AUTOSAR XML (schema 4.0)
standard types defined: float32, float64, sint16, sint32, sint8, uint16, uint32, uint8, void, boolean
package /MappingSets
  data type mapping set MappingSet
package /PortInterfaces/ClientServer
  7 x client server interface:
    CsIf_HeightMotor
      operation Opr_MoveOperation
        arg Arg_MotorRead: type=uint8, direction=IN
    CsIf_HeightSensor
      operation Opr_GetPosition
        arg Arg_position: type=uint8, direction=OUT
    CsIf_InclineMotor
      operation Opr_MoveOperation
        arg Arg_MotorRead: type=uint8, direction=IN
    CsIf_InclineSensor
      operation Opr_GetPosition
        arg Arg_position: type=uint8, direction=OUT
    CsIf_SlideMotor
      operation Opr_MoveOperation
        arg Arg_MotorRead: type=uint8, direction=IN
    CsIf_SlideSensor
      operation Opr_GetPosition
        arg Arg_position: type=uint8, direction=OUT
    CsIf_WeightSensor
      operation Opr_GetWeight
        arg Arg_weight: type=uint8, direction=OUT
package /SoftwareComponents
  8 x swc implementation, all with programming-language=C, sw-version=1.0.0, vendor-id=255:
    Impl_SWC_HeightMotor: behavior=Ibhv_SWC_HeightMotor
      code-descriptors:
        code Code: artifact-descriptors=autosar-engineering-object={short-label=SWC.c, category=SWSRC}
      resource consumption ResourceConsumption
    Impl_SWC_HeightSensor: behavior=Ibhv_SWC_HeightSensor
      code-descriptors:
        code Code: artifact-descriptors=autosar-engineering-object={short-label=SWC.c, category=SWSRC}
      resource consumption ResourceConsumption
    Impl_SWC_InclineMotor: behavior=Ibhv_SWC_InclineMotor
      code-descriptors:
        code Code: artifact-descriptors=autosar-engineering-object={short-label=SWC.c, category=SWSRC}
      resource consumption ResourceConsumption
    Impl_SWC_InclineSensor: behavior=Ibhv_SWC_InclineSensor
      code-descriptors:
        code Code: artifact-descriptors=autosar-engineering-object={short-label=SWC.c, category=SWSRC}
      resource consumption ResourceConsumption
    Impl_SWC_SeatManager: behavior=Ibhv_SWC_SeatManager
      code-descriptors:
        code Code: artifact-descriptors=autosar-engineering-object={short-label=SWC.c, category=SWSRC}
      resource consumption ResourceConsumption
    Impl_SWC_SlideMotor: behavior=Ibhv_SWC_SlideMotor
      code-descriptors:
        code Code: artifact-descriptors=autosar-engineering-object={short-label=SWC.c, category=SWSRC}
      resource consumption ResourceConsumption
    Impl_SWC_SlideSensor: behavior=Ibhv_SWC_SlideSensor
      code-descriptors:
        code Code: artifact-descriptors=autosar-engineering-object={short-label=SWC.c, category=SWSRC}
      resource consumption ResourceConsumption
    Impl_SWC_WeightSensor: behavior=Ibhv_SWC_WeightSensor
      code-descriptors:
        code Code: artifact-descriptors=autosar-engineering-object={short-label=SWC.c, category=SWSRC}
      resource consumption ResourceConsumption
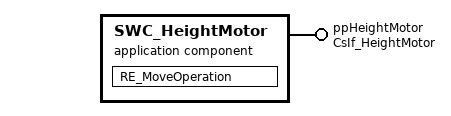
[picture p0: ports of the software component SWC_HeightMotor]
  application sw component type SWC_HeightMotor
    provide port ppHeightMotor: provided-interface=CsIf_HeightMotor
    behavior Ibhv_SWC_HeightMotor: data-type-mapping=MappingSet, handle-termination-and-restart=NO-SUPPORT
      operation invoked event OIE_ppHeightMotor_Opr_MoveOperation: start-on-event=Ibhv_SWC_HeightMotor/RE_MoveOperation, operation=ppHeightMotor.Opr_MoveOperation
      runnable RE_MoveOperation
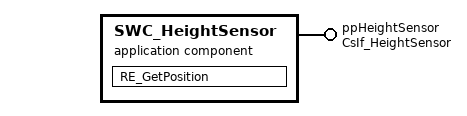
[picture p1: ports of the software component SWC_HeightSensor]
  application sw component type SWC_HeightSensor
    provide port ppHeightSensor: provided-interface=CsIf_HeightSensor
    behavior Ibhv_SWC_HeightSensor: data-type-mapping=MappingSet, handle-termination-and-restart=NO-SUPPORT
      operation invoked event OIE_ppHeightSensor_Opr_GetPosition: start-on-event=Ibhv_SWC_HeightSensor/RE_GetPosition, operation=ppHeightSensor.Opr_GetPosition
      runnable RE_GetPosition
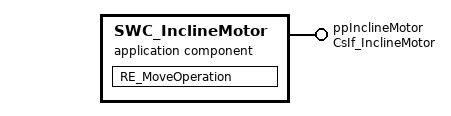
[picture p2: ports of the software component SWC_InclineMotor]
  application sw component type SWC_InclineMotor
    provide port ppInclineMotor: provided-interface=CsIf_InclineMotor
    behavior Ibhv_SWC_InclineMotor: data-type-mapping=MappingSet, handle-termination-and-restart=NO-SUPPORT
      runnable RE_MoveOperation
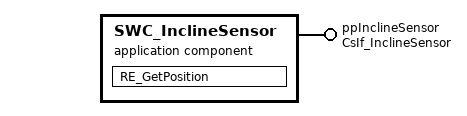
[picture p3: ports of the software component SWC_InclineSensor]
  application sw component type SWC_InclineSensor
    provide port ppInclineSensor: provided-interface=CsIf_InclineSensor
    behavior Ibhv_SWC_InclineSensor: data-type-mapping=MappingSet, handle-termination-and-restart=NO-SUPPORT
      operation invoked event OIE_ppInclineSensor_Opr_GetPosition: start-on-event=Ibhv_SWC_InclineSensor/RE_GetPosition, operation=ppInclineSensor.Opr_GetPosition
      runnable RE_GetPosition
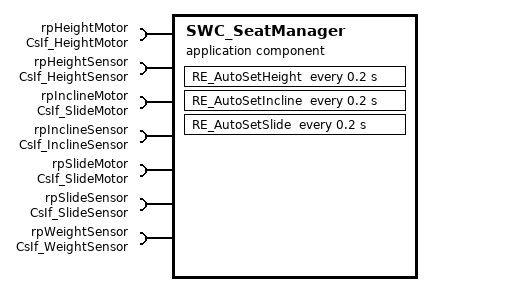
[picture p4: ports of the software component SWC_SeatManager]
  application sw component type SWC_SeatManager
    7 x require port:
      rpHeightMotor: required-interface=CsIf_HeightMotor
      rpHeightSensor: required-interface=CsIf_HeightSensor
      rpInclineMotor: required-interface=CsIf_SlideMotor
      rpInclineSensor: required-interface=CsIf_InclineSensor
      rpSlideMotor: required-interface=CsIf_SlideMotor
      rpSlideSensor: required-interface=CsIf_SlideSensor
      rpWeightSensor: required-interface=CsIf_WeightSensor
    behavior Ibhv_SWC_SeatManager: data-type-mapping=MappingSet, handle-termination-and-restart=NO-SUPPORT
      timing event TE_RE_AutoSetHeight_200ms: start-on-event=RE_AutoSetHeight, period=0.2
      timing event TE_RE_AutoSetIncline_200ms: start-on-event=RE_AutoSetIncline, period=0.2
      timing event TE_RE_AutoSetSlide_200ms: start-on-event=RE_AutoSetSlide, period=0.2
      runnable RE_AutoSetHeight
        sync call SCP_rpHeightMotor_Opr_MoveOperation: operation=rpHeightMotor.Opr_MoveOperation, timeout=0.0
        sync call SCP_rpHeightSensor_Opr_GetPosition: operation=rpHeightSensor.Opr_GetPosition, timeout=0.0
        sync call SCP_rpWeightSensor_Opr_GetWeight: operation=rpWeightSensor.Opr_GetWeight, timeout=0.0
      runnable RE_AutoSetIncline
        sync call SCP_rpInclineMotor_Opr_MoveOperation: operation=rpInclineMotor.Opr_MoveOperation, timeout=0.0
        sync call SCP_rpInclineSensor_Opr_GetPosition: operation=rpInclineSensor.Opr_GetPosition, timeout=0.0
        sync call SCP_rpWeightSensor_Opr_GetWeight: operation=rpWeightSensor.Opr_GetWeight, timeout=0.0
      runnable RE_AutoSetSlide
        sync call SCP_rpSlideMotor_Opr_MoveOperation: operation=rpSlideMotor.Opr_MoveOperation, timeout=0.0
        sync call SCP_rpSlideSensor_Opr_GetPosition: operation=rpSlideSensor.Opr_GetPosition, timeout=0.0
        sync call SCP_rpWeightSensor_Opr_GetWeight: operation=rpWeightSensor.Opr_GetWeight, timeout=0.0
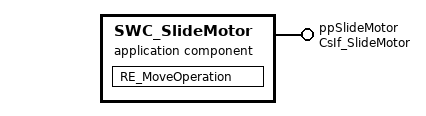
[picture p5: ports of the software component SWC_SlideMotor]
  application sw component type SWC_SlideMotor
    provide port ppSlideMotor: provided-interface=CsIf_SlideMotor
    behavior Ibhv_SWC_SlideMotor: data-type-mapping=MappingSet, handle-termination-and-restart=NO-SUPPORT
      runnable RE_MoveOperation
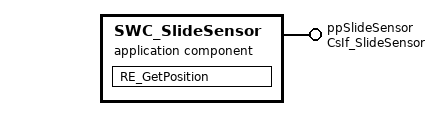
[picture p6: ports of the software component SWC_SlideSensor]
  application sw component type SWC_SlideSensor
    provide port ppSlideSensor: provided-interface=CsIf_SlideSensor
    behavior Ibhv_SWC_SlideSensor: data-type-mapping=MappingSet, handle-termination-and-restart=NO-SUPPORT
      operation invoked event OIE_ppSlideSensor_Opr_GetPosition: start-on-event=Ibhv_SWC_SlideSensor/RE_GetPosition, operation=ppSlideSensor.Opr_GetPosition
      runnable RE_GetPosition
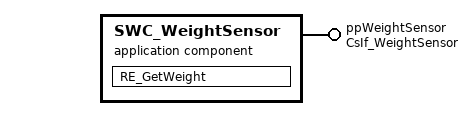
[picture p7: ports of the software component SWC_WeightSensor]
  application sw component type SWC_WeightSensor
    provide port ppWeightSensor: provided-interface=CsIf_WeightSensor
    behavior Ibhv_SWC_WeightSensor: data-type-mapping=MappingSet, handle-termination-and-restart=NO-SUPPORT
      operation invoked event OIE_ppWeightSensor_Opr_GetWeight: start-on-event=RE_GetWeight, operation=ppWeightSensor.Opr_GetWeight
      runnable RE_GetWeight
package /Compositions
  composition sw component type TestApp3Composition
    5 x component:
      SWC_HeightSensor: type=SWC_HeightSensor
      SWC_InclineSensor: type=SWC_InclineSensor
      SWC_SeatManager: type=SWC_SeatManager
      SWC_SlideSensor: type=SWC_SlideSensor
      SWC_WeightSensor: type=SWC_WeightSensor
    connect SWC_HeightSensor.ppHeightSensor -> SWC_SeatManager.rpHeightSensor
    connect SWC_InclineSensor.ppInclineSensor -> SWC_SeatManager.rpInclineSensor
    connect SWC_SlideSensor.ppSlideSensor -> SWC_SeatManager.rpSlideSensor
    connect SWC_WeightSensor.ppWeightSensor -> SWC_SeatManager.rpWeightSensor
